# STM32L552 register map
File version: 1.0
CPU: CM33 r0p1, little endian, MPU, FPU, 3 interrupt priority bits
Registers are 32-bit, read-write, reset 0x0 unless marked. A register's access mark holds for its fields unless they carry their own. Offsets are from the block's base; [hi:lo] are bit positions.

## RNG
Base 0x420C0800
Same registers: SEC_RNG 0x520C0800
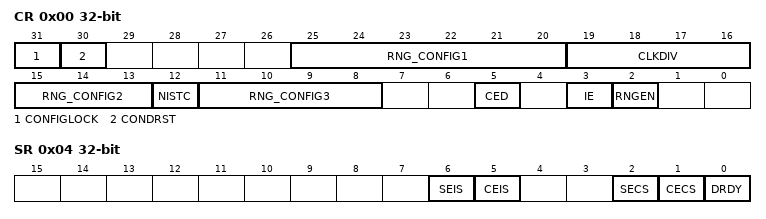
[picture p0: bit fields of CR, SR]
0x00 CR — RNG control register
  [31] CONFIGLOCK — RNG Config Lock
    0=Enabled (Writes to the RNG_CR configuration bits [29:4] are allowed); 1=Disabled (Writes to the RNG_CR configuration bits [29:4] are ignored until the next RNG reset)
  [30] CONDRST — Conditioning soft reset
  [25:20] RNG_CONFIG1 — RNG configuration 1
    15=ConfigA (Recommended value for config A (NIST certifiable)); 24=ConfigB (Recommended value for config B (not NIST certifiable))
  [19:16] CLKDIV — Clock divider factor
    0=Div1 (Internal RNG clock after divider is similar to incoming RNG clock); 1=Div2 (Divide RNG clock by 2^1); 2=Div4 (Divide RNG clock by 2^2); 3=Div8 (Divide RNG clock by 2^3); 4=Div16 (Divide RNG clock by 2^4); 5=Div32 (Divide RNG clock by 2^5); 6=Div64 (Divide RNG clock by 2^6); 7=Div128 (Divide RNG clock by 2^7); 8=Div256 (Divide RNG clock by 2^8); 9=Div512 (Divide RNG clock by 2^9); 10=Div1024 (Divide RNG clock by 2^10); 11=Div2048 (Divide RNG clock by 2^11); 12=Div4096 (Divide RNG clock by 2^12); 13=Div8192 (Divide RNG clock by 2^13); 14=Div16384 (Divide RNG clock by 2^14); 15=Div32768 (Divide RNG clock by 2^15)
  [15:13] RNG_CONFIG2 — RNG configuration 2
    0=ConfigA_B (Recommended value for config A and B)
  [12] NISTC — Non NIST compliant
    0=Default (Hardware default values for NIST compliant RNG. In this configuration per 128-bit output two conditioning loops are performed and 256 bits of noise source are used); 1=Custom values for NIST compliant RNG
  [11:8] RNG_CONFIG3 — RNG configuration 3
    0=ConfigB (Recommended value for config B (not NIST certifiable)); 13=ConfigA (Recommended value for config A (NIST certifiable))
  [5] CED — Clock error detection Note: The clock error detection can be used only when ck_rc48 or ck_pll1_q (ck_pll1_q = 48MHz) source is selected otherwise, CED bit must be equal to 1. The clock error detection cannot be enabled nor disabled on the fly when RNG peripheral is enabled, to enable or disable CED the RNG must be disabled.
    0=Enabled (Clock error detection is enabled); 1=Disabled (Clock error detection is disabled)
  [3] IE — Interrupt enable
    0=Disabled (RNG interrupt is disabled); 1=Enabled (RNG interrupt is enabled)
  [2] RNGEN — Random number generator enable
    0=Disabled (Random number generator is disabled); 1=Enabled (Random number generator is enabled)
0x04 SR access per field — RNG status register
  [6] SEIS rw write-0-clears — Seed error interrupt status This bit is set at the same time as SECS. It is cleared by writing it to 0. ** More than 64 consecutive bits at the same value (0 or 1) ** More than 32 consecutive alternances of 0 and 1 (0101010101...01) An interrupt is pending if IE = 1 in the RNG_CR register.
    on write: 0=Clear flag | on read: 0=No faulty sequence detected; 1=Fault (At least one faulty sequence has been detected. See **SECS** bit description for details. An interrupt is pending if IE = 1 in the RNG_CR register.)
  [5] CEIS rw write-0-clears — Clock error interrupt status This bit is set at the same time as CECS. It is cleared by writing it to 0. An interrupt is pending if IE = 1 in the RNG_CR register. Note: This bit is meaningless if CED (Clock error detection) bit in RNG_CR is equal to 1.
    on write: 0=Clear flag | on read: 0=Correct (The RNG clock is correct); 1=Slow (The RNG has been detected too slow An interrupt is pending if IE = 1 in the RNG_CR register)
  [2] SECS ro — Seed error current status ** More than 64 consecutive bits at the same value (0 or 1) ** More than 32 consecutive alternances of 0 and 1 (0101010101...01)
    0=No faulty sequence has currently been detected. If the SEIS bit is set, this means that a faulty sequence was detected and the situation has been recovered.; 1=Fault (At least one faulty sequence has been detected - see ref manual for details)
  [1] CECS ro — Clock error current status Note: This bit is meaningless if CED (Clock error detection) bit in RNG_CR is equal to 1.
    0=Correct (The RNG clock is correct. If the CEIS bit is set, this means that a slow clock was detected and the situation has been recovered.); 1=Slow (The RNG clock is too slow)
  [0] DRDY ro — Data ready Note: If IE=1 in RNG_CR, an interrupt is generated when DRDY=1. It can rise when the peripheral is disabled. When the output buffer becomes empty (after reading RNG_DR), this bit returns to 0 until a new random value is generated.
    0=Invalid (The RNG_DR register is not yet valid, no random data is available); 1=Valid (The RNG_DR register contains valid random data. Once the RNG_DR register has been read, this bit returns to 0 until a new random value is generated.)
0x08 DR ro — The RNG_DR register is a read-only register that delivers a 32-bit random value when read. The content of this register is valid when DRDY= 1, even if RNGEN=0.
  [31:0] RNDATA — Random data 32-bit random data which are valid when DRDY=1.
0x10 HTCR reset 0xCAA74 — The RNG_DR register is a read-only register that delivers a 32-bit random value when read. The content of this register is valid when DRDY= 1, even if RNGEN=0.
  [31:0] HTCFG — health test configuration
    0xAA74=Recommended value for RNG certification (0x0000_AA74); 0x17590ABC=Magic number to be written before any write (0x1759_0ABC)
